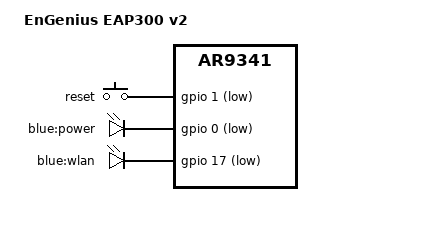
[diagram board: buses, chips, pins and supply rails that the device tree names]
// SPDX-License-Identifier: GPL-2.0-or-later OR MIT

#include "ar934x_senao_ap.dtsi"

/ {
	compatible = "engenius,eap300-v2", "qca,ar9341";
	model = "EnGenius EAP300 v2";

	keys {
		compatible = "gpio-keys";

		reset {
			label = "reset";
			gpios = <&gpio 1 GPIO_ACTIVE_LOW>;
			debounce-interval = <60>;
			linux,code = <KEY_RESTART>;
		};
	};

	leds {
		compatible = "gpio-leds";

		led_power: power {
			label = "blue:power";
			gpios = <&gpio 0 GPIO_ACTIVE_LOW>;
			default-state = "on";
		};

		wlan {
			label = "blue:wlan";
			gpios = <&gpio 17 GPIO_ACTIVE_LOW>;
			linux,default-trigger = "phy0tpt";
		};
	};
};

&eth1 {
	mtd-mac-address = <&art 0x0>;
};
